# AC78xx register map
Vendor: AutoChips; Series: AC78xx; File version: 1.0
CPU: CM3 r2p1, little endian, MPU, no FPU, 3 interrupt priority bits
Registers are 32-bit, read-write, no defined reset value unless marked. A register's access mark holds for its fields unless they carry their own. Offsets are from the block's base; [hi:lo] are bit positions; {n}, {i} and the like mark numbered series; 'fields as' and 'values as' point back to an identical list.

## ACMP0 — Analog comparator
Base 0x40005000; register names take the prefix ACMP0_
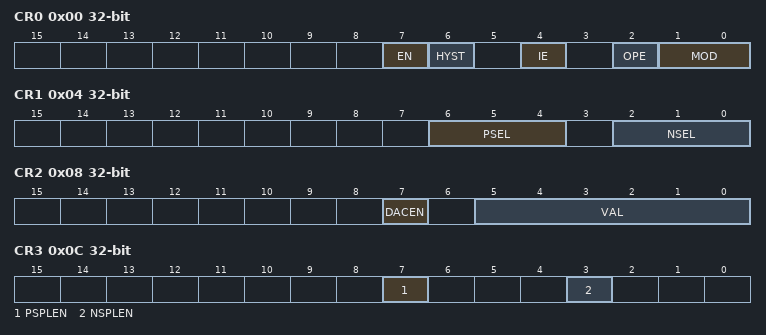
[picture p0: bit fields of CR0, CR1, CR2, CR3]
0x00 CR0 — ACMP0 Configuration Register 0
  [7] EN — Analog Comparator Enable
    0=The ACMP is disabled; 1=The ACMP is enabled
  [6] HYST — Analog Comparator Hysterisis Selection
    0=20 mV; 1=30 mV
  [4] IE — ACMP0 Interrupt Enable
    0=Disable the ACMP Interrupt; 1=Enable the ACMP Interrupt
  [2] OPE — ACMP0 hall output Enable
    0=ACMP0 hall output Disabled; 1=ACMP0 hall output enabled
  [1:0] MOD — ACMP0 sensitivity modes of the interrupt trigger
    0=ACMP0 interrupt on output falling edge; 1=ACMP0 interrupt on output rising edge; 2=ACMP0 interrupt on output falling edge; 3=ACMP0 interrupt on output falling or rising edge
0x04 CR1 — ACMP Configuration Register 1
  [6:4] PSEL — ACMP0 Positive Input Select
    {v}=External input {v} (v=0..4); 5=DAC0 Output; 6=ACMP0 output tie 0; 7=ACMP0 output tie 0
  [2:0] NSEL — ACMP0 Negative Input Select
    values as PSEL
0x08 CR2 — ACMP0 configuration register 2
  [7] DACEN — DAC Enable
    0=The DAC0 is disabled; 1=The DAC0 is enabled
  [5:0] VAL — DAC0 Output Level Selection
0x0C CR3 — ACMP0 configuration register 3
  [7] PSPLEN — ACMP0 positive input polling mode enable
    0=ACMP0 positive input polling mode disabled; 1=ACMP0 positive input polling mode enabled
  [3] NSPLEN — ACMP0 negative input polling mode enable
    0=ACMP0 negative input polling mode disabled; 1=ACMP0 negative input polling mode enabled
0x10 CR4 — ACMP0 configuration register 4
  [5:0] PLSEQ — ACMP0 polling channel sequence set
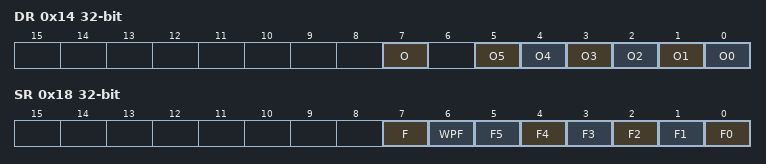
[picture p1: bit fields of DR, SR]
0x14 DR — ACMP0 data output register 0
  [7] O — ACMP0 normal mode output
  [n] O{n} (n=0..5) — ACMP0 polling mode channel {n} output
0x18 SR — ACMP0 status register 0
  [7] F — ACMP0 normal mode interrupt flag
  [6] WPF — ACMP0 low power mode wakeup interrupt flag
  [n] F{n} (n=0..5) — ACMP0 polling mode channel {n} interrupt flag
0x1C FD — ACMP0 polling frequency divider register
  [1:0] PLFD — ACMP0 polling mode frequency divider
    0=source_clk/256; 1=source_clk/100; 2=source_clk/70; 3=source_clk/50
0x20 OPA — ACMP0 hall output A set register
  [2:0] OPASEL — ACMP0 Hall output A set
    {v}=polling channel {v} (v=0..5); 6=ACMP0 output tie 0; 7=ACMP0 output tie 0
0x24 OPB — ACMP0 hall output B set register
  [2:0] OPBSEL — ACMP0 Hall output B set
    values as OPA.OPASEL
0x28 OPC — ACMP0 hall output C set register
  [2:0] OPCSEL — ACMP0 Hall output C set
    values as OPA.OPASEL
0x2C DACSR — ACMP DAC reference select register
  [0] DACREF — ACMP DAC reference select
    0=DAC selects bandgap as reference; 1=DAC selects Vdd as reference

## ACMP1 — Analog comparator
Base 0x40005030; register names take the prefix ACMP0_
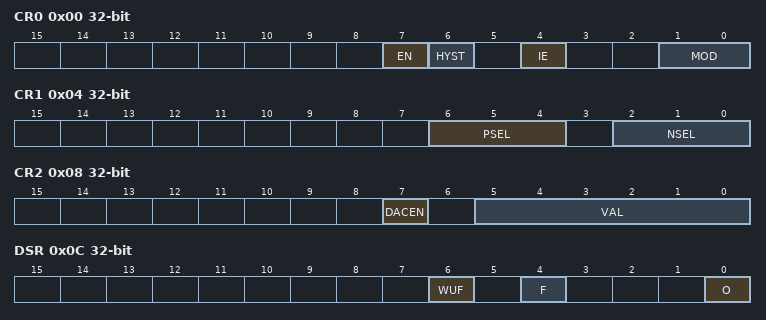
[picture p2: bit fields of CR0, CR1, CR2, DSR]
0x00 CR0 — ACMP1 Configuration Register 0
  [7] EN — Analog Comparator Enable
    0=The ACMP1 is disabled; 1=The ACMP1 is enabled
  [6] HYST — Analog Comparator Hysterisis Selection
    0=20 mV; 1=30 mV
  [4] IE — ACMP1 Interrupt Enable
    0=Disable the ACMP1 Interrupt; 1=Enable the ACMP1 Interrupt
  [1:0] MOD — ACMP1 sensitivity modes of the interrupt trigger
    0=ACMP1 interrupt on output falling edge; 1=ACMP1 interrupt on output rising edge; 2=ACMP1 interrupt on output falling edge; 3=ACMP1 interrupt on output falling or rising edge
0x04 CR1 — ACMP1 Configuration Register 1
  [6:4] PSEL — ACMP1 Positive Input Select
    {v}=External input {v} (v=0..4); 5=DAC1 Output; 6=ACMP1 output tie 0; 7=ACMP1 output tie 0
  [2:0] NSEL — ACMP1 Negative Input Select
    values as PSEL
0x08 CR2 — ACMP1 configuration register 2
  [7] DACEN — DAC1 Enable
    0=The DAC1 is disabled; 1=The DAC1 is enabled
  [5:0] VAL — DAC1 Output Level Selection
0x0C DSR — ACMP0 data output register 0
  [6] WUF — ACMP1 low power wakeup interrupt flag
  [4] F — ACMP1 interrupt Flag
  [0] O — ACMP1 output

## Notices in the file
Copyright (C) 2012-2014 ARM Limited. All rights reserved.
Purpose: System Viewer Description (SVD) Example (Schema Version 1.1)
This is a description of a none-existent and incomplete device
for demonstration purposes only.
Redistribution and use in source and binary forms, with or without
modification, are permitted provided that the following conditions are met:
- Redistributions of source code must retain the above copyright
notice, this list of conditions and the following disclaimer.
- Redistributions in binary form must reproduce the above copyright
notice, this list of conditions and the following disclaimer in the
documentation and/or other materials provided with the distribution.
- Neither the name of ARM nor the names of its contributors may be used
to endorse or promote products derived from this software without
specific prior written permission.
THIS SOFTWARE IS PROVIDED BY THE COPYRIGHT HOLDERS AND CONTRIBUTORS "AS IS"
AND ANY EXPRESS OR IMPLIED WARRANTIES, INCLUDING, BUT NOT LIMITED TO, THE
IMPLIED WARRANTIES OF MERCHANTABILITY AND FITNESS FOR A PARTICULAR PURPOSE
ARE DISCLAIMED. IN NO EVENT SHALL COPYRIGHT HOLDERS AND CONTRIBUTORS BE
LIABLE FOR ANY DIRECT, INDIRECT, INCIDENTAL, SPECIAL, EXEMPLARY, OR
CONSEQUENTIAL DAMAGES (INCLUDING, BUT NOT LIMITED TO, PROCUREMENT OF
SUBSTITUTE GOODS OR SERVICES; LOSS OF USE, DATA, OR PROFITS; OR BUSINESS
INTERRUPTION) HOWEVER CAUSED AND ON ANY THEORY OF LIABILITY, WHETHER IN
CONTRACT, STRICT LIABILITY, OR TORT (INCLUDING NEGLIGENCE OR OTHERWISE)
ARISING IN ANY WAY OUT OF THE USE OF THIS SOFTWARE, EVEN IF ADVISED OF THE
POSSIBILITY OF SUCH DAMAGE.
